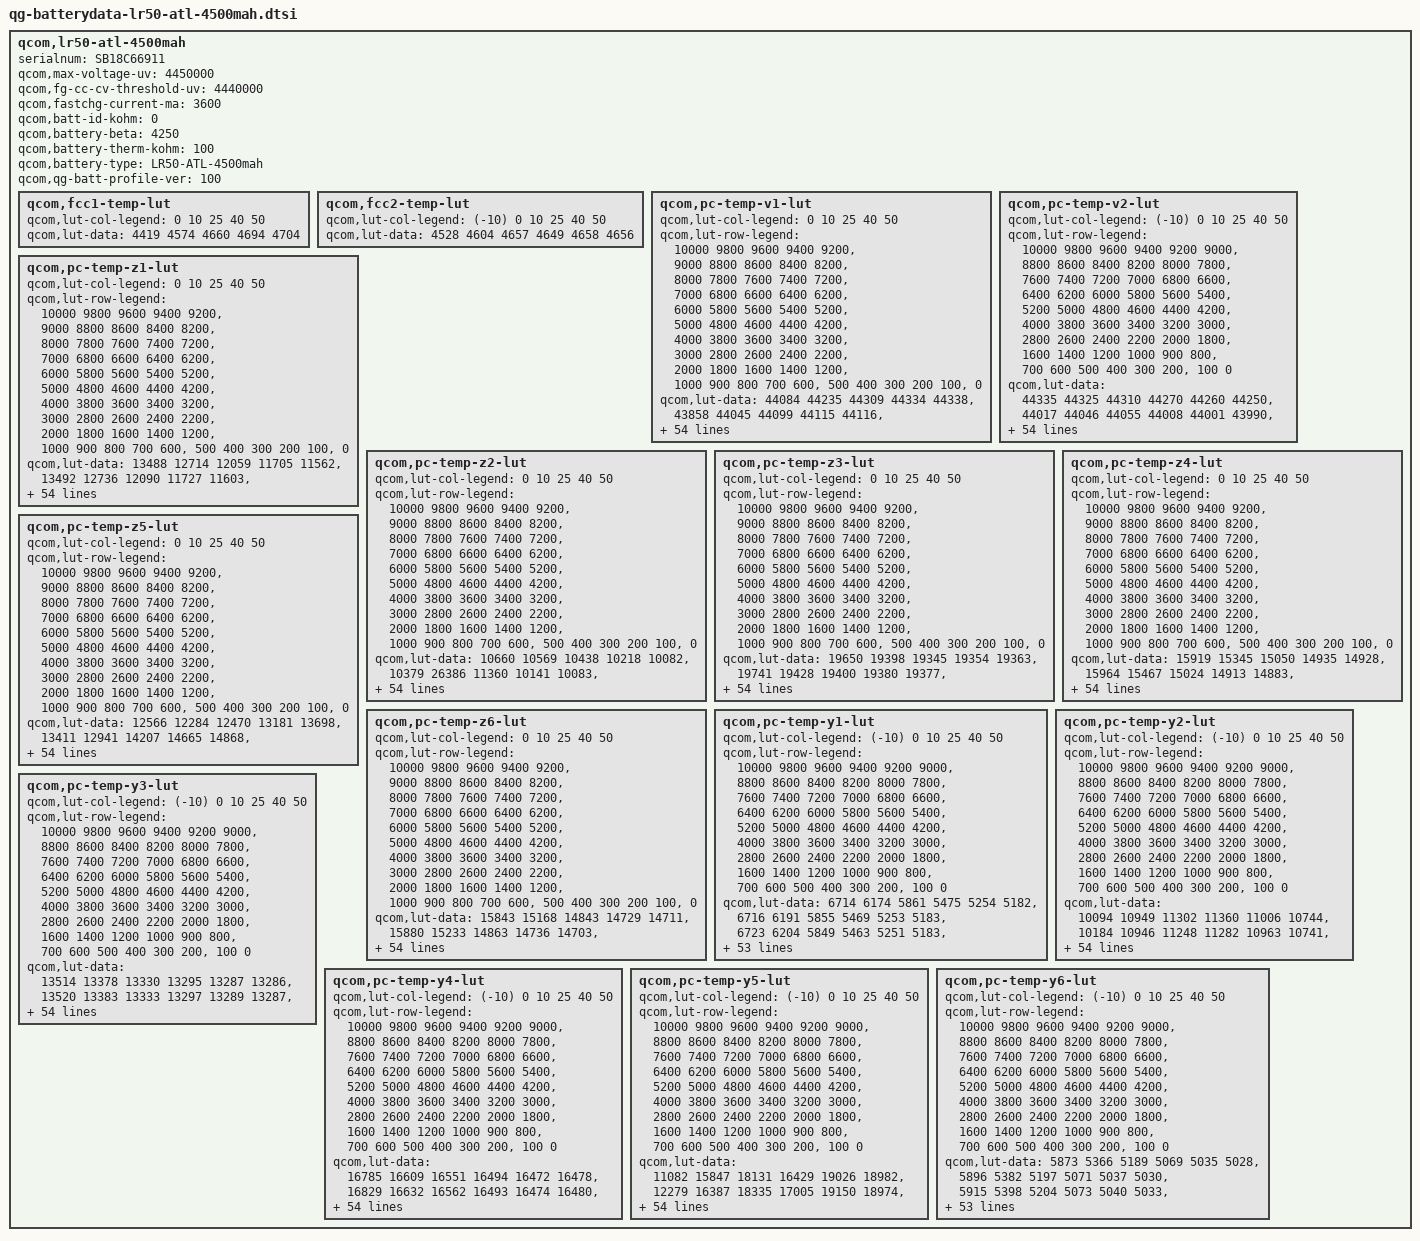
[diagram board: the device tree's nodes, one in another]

qcom,lr50-atl-4500mah {
	serialnum = "SB18C66911";
	qcom,max-voltage-uv = <4450000>;
	qcom,fg-cc-cv-threshold-uv = <4440000>;
	qcom,fastchg-current-ma = <3600>;
	qcom,batt-id-kohm = <0>;
	qcom,battery-beta = <4250>;
	qcom,battery-therm-kohm = <100>;
	qcom,battery-type = "LR50-ATL-4500mah";
	qcom,qg-batt-profile-ver = <100>;

	qcom,fcc1-temp-lut {
		qcom,lut-col-legend = <0 10 25 40 50>;
		qcom,lut-data = <4419 4574 4660 4694 4704>;
	};

	qcom,fcc2-temp-lut {
		qcom,lut-col-legend = <(-10) 0 10 25 40 50>;
		qcom,lut-data = <4528 4604 4657 4649 4658 4656>;
	};

	qcom,pc-temp-v1-lut {
		qcom,lut-col-legend = <0 10 25 40 50>;
		qcom,lut-row-legend = <10000 9800 9600 9400 9200>,
			<9000 8800 8600 8400 8200>,
			<8000 7800 7600 7400 7200>,
			<7000 6800 6600 6400 6200>,
			<6000 5800 5600 5400 5200>,
			<5000 4800 4600 4400 4200>,
			<4000 3800 3600 3400 3200>,
			<3000 2800 2600 2400 2200>,
			<2000 1800 1600 1400 1200>,
			<1000 900 800 700 600>,
			<500 400 300 200 100>,
			<0>;
		qcom,lut-data = <44084 44235 44309 44334 44338>,
			<43858 44045 44099 44115 44116>,
			<43631 43827 43902 43912 43913>,
			<43404 43604 43689 43709 43714>,
			<43174 43377 43467 43497 43504>,
			<42936 43142 43237 43274 43283>,
			<42692 42903 43000 43041 43050>,
			<42451 42657 42759 42802 42811>,
			<42212 42409 42511 42557 42569>,
			<41976 42165 42263 42309 42324>,
			<41746 41924 42019 42066 42081>,
			<41521 41688 41777 41825 41839>,
			<41301 41458 41541 41589 41600>,
			<41092 41235 41309 41355 41365>,
			<40885 41020 41086 41127 41135>,
			<40676 40812 40876 40907 40914>,
			<40465 40607 40673 40695 40700>,
			<40268 40403 40472 40493 40498>,
			<40091 40209 40275 40300 40308>,
			<39925 40039 40091 40115 40125>,
			<39762 39873 39930 39948 39957>,
			<39606 39673 39746 39773 39782>,
			<39445 39427 39449 39529 39543>,
			<39263 39198 39121 39235 39246>,
			<39074 38994 38955 39038 39046>,
			<38904 38816 38863 38920 38936>,
			<38740 38700 38778 38818 38838>,
			<38610 38617 38683 38713 38720>,
			<38528 38543 38592 38614 38602>,
			<38464 38469 38506 38519 38503>,
			<38408 38402 38426 38428 38418>,
			<38355 38339 38352 38345 38339>,
			<38308 38283 38284 38271 38264>,
			<38267 38231 38221 38203 38193>,
			<38230 38186 38165 38136 38124>,
			<38195 38143 38113 38074 38058>,
			<38163 38103 38061 38013 37991>,
			<38127 38065 38014 37960 37925>,
			<38075 38012 37955 37896 37849>,
			<38002 37927 37870 37801 37746>,
			<37914 37821 37765 37683 37623>,
			<37794 37705 37649 37566 37500>,
			<37662 37569 37516 37441 37372>,
			<37528 37404 37355 37287 37209>,
			<37365 37251 37200 37139 37066>,
			<37226 37142 37098 37048 36992>,
			<37178 37118 37066 37016 36960>,
			<37142 37089 37042 36992 36938>,
			<37112 37063 37024 36973 36915>,
			<37082 37031 36988 36928 36862>,
			<37034 36878 36804 36716 36626>,
			<36831 36461 36389 36291 36196>,
			<36360 35869 35815 35719 35623>,
			<35706 35018 35030 34939 34842>,
			<34574 33637 33812 33745 33641>,
			<30000 30000 30000 30000 30000>;
	};

	qcom,pc-temp-v2-lut {
		qcom,lut-col-legend = <(-10) 0 10 25 40 50>;
		qcom,lut-row-legend = <10000 9800 9600 9400 9200 9000>,
			<8800 8600 8400 8200 8000 7800>,
			<7600 7400 7200 7000 6800 6600>,
			<6400 6200 6000 5800 5600 5400>,
			<5200 5000 4800 4600 4400 4200>,
			<4000 3800 3600 3400 3200 3000>,
			<2800 2600 2400 2200 2000 1800>,
			<1600 1400 1200 1000 900 800>,
			<700 600 500 400 300 200>,
			<100 0>;
		qcom,lut-data = <44335 44325 44310 44270 44260 44250>,
			<44017 44046 44055 44008 44001 43990>,
			<43730 43786 43812 43758 43755 43743>,
			<43478 43550 43583 43524 43523 43512>,
			<43261 43337 43368 43305 43307 43296>,
			<43043 43115 43144 43079 43082 43074>,
			<42811 42874 42901 42838 42845 42839>,
			<42572 42626 42653 42593 42602 42599>,
			<42327 42380 42405 42346 42358 42356>,
			<42073 42133 42156 42099 42112 42109>,
			<41823 41893 41911 41856 41868 41866>,
			<41581 41658 41670 41618 41627 41627>,
			<41344 41429 41434 41384 41391 41391>,
			<41115 41202 41203 41153 41160 41160>,
			<40894 40979 40978 40928 40935 40935>,
			<40657 40751 40765 40711 40718 40717>,
			<40379 40518 40563 40500 40510 40506>,
			<40094 40277 40349 40300 40310 40304>,
			<39846 40017 40104 40122 40123 40117>,
			<39621 39751 39851 39941 39939 39935>,
			<39413 39521 39607 39723 39743 39747>,
			<39220 39319 39369 39470 39539 39556>,
			<39036 39134 39162 39235 39325 39349>,
			<38842 38963 38984 39020 39081 39100>,
			<38640 38804 38825 38831 38863 38874>,
			<38474 38654 38681 38685 38713 38722>,
			<38344 38513 38551 38563 38592 38600>,
			<38238 38382 38432 38452 38480 38487>,
			<38158 38253 38323 38350 38376 38382>,
			<38094 38137 38221 38256 38281 38285>,
			<38037 38043 38125 38168 38198 38200>,
			<37985 37963 38036 38087 38122 38121>,
			<37935 37902 37953 38015 38047 38046>,
			<37880 37857 37873 37951 37974 37975>,
			<37824 37818 37809 37887 37899 37897>,
			<37766 37779 37763 37820 37824 37810>,
			<37705 37741 37722 37751 37746 37716>,
			<37640 37697 37677 37677 37655 37615>,
			<37567 37643 37630 37598 37556 37508>,
			<37487 37576 37566 37514 37459 37409>,
			<37404 37479 37472 37425 37366 37320>,
			<37315 37359 37360 37324 37270 37226>,
			<37222 37238 37225 37207 37166 37120>,
			<37125 37096 37063 37065 36999 36942>,
			<37037 36943 36915 36942 36903 36850>,
			<36944 36822 36832 36888 36853 36806>,
			<36897 36781 36797 36873 36842 36795>,
			<36848 36739 36764 36855 36830 36778>,
			<36799 36698 36709 36834 36807 36751>,
			<36751 36647 36622 36773 36736 36671>,
			<36690 36569 36385 36556 36475 36375>,
			<36596 36340 35899 36063 35973 35870>,
			<36402 35757 35201 35433 35331 35219>,
			<35976 34829 34181 34595 34468 34346>,
			<35065 33516 32703 33336 33235 33072>,
			<33973 31884 28001 28237 28418 28444>;
	};

	qcom,pc-temp-z1-lut {
		qcom,lut-col-legend = <0 10 25 40 50>;
		qcom,lut-row-legend = <10000 9800 9600 9400 9200>,
			<9000 8800 8600 8400 8200>,
			<8000 7800 7600 7400 7200>,
			<7000 6800 6600 6400 6200>,
			<6000 5800 5600 5400 5200>,
			<5000 4800 4600 4400 4200>,
			<4000 3800 3600 3400 3200>,
			<3000 2800 2600 2400 2200>,
			<2000 1800 1600 1400 1200>,
			<1000 900 800 700 600>,
			<500 400 300 200 100>,
			<0>;
		qcom,lut-data = <13488 12714 12059 11705 11562>,
			<13492 12736 12090 11727 11603>,
			<13498 12735 12092 11723 11603>,
			<13507 12733 12084 11721 11602>,
			<13513 12728 12072 11719 11603>,
			<13504 12715 12062 11716 11602>,
			<13478 12702 12052 11713 11599>,
			<13457 12683 12042 11710 11598>,
			<13440 12663 12032 11706 11598>,
			<13429 12647 12026 11703 11599>,
			<13429 12633 12023 11703 11600>,
			<13433 12624 12022 11704 11600>,
			<13435 12619 12021 11705 11601>,
			<13421 12615 12021 11704 11601>,
			<13400 12611 12020 11703 11602>,
			<13386 12608 12019 11704 11603>,
			<13372 12606 12017 11704 11604>,
			<13362 12601 12018 11705 11605>,
			<13353 12598 12020 11706 11606>,
			<13344 12603 12022 11708 11607>,
			<13342 12610 12023 11709 11608>,
			<13347 12613 12025 11711 11610>,
			<13352 12615 12026 11711 11611>,
			<13358 12616 12028 11712 11612>,
			<13367 12617 12031 11713 11613>,
			<13370 12619 12036 11717 11616>,
			<13382 12621 12040 11721 11619>,
			<13392 12624 12045 11725 11622>,
			<13395 12630 12050 11728 11626>,
			<13399 12643 12056 11732 11629>,
			<13401 12657 12064 11735 11632>,
			<13402 12660 12070 11739 11636>,
			<13404 12660 12076 11744 11641>,
			<13403 12662 12081 11749 11645>,
			<13399 12667 12087 11754 11649>,
			<13401 12675 12093 11759 11652>,
			<13422 12685 12099 11764 11656>,
			<13446 12700 12106 11769 11661>,
			<13464 12712 12113 11774 11665>,
			<13496 12723 12122 11777 11668>,
			<13513 12733 12131 11781 11671>,
			<13519 12741 12139 11785 11674>,
			<13528 12749 12146 11790 11678>,
			<13547 12765 12156 11794 11681>,
			<13565 12776 12170 11799 11684>,
			<13581 12783 12183 11806 11686>,
			<13566 12787 12181 11804 11685>,
			<13516 12798 12179 11803 11685>,
			<13531 12788 12182 11805 11687>,
			<13516 12788 12187 11809 11691>,
			<13527 12809 12207 11815 11695>,
			<13596 12836 12214 11824 11701>,
			<13609 12838 12229 11835 11712>,
			<13618 12861 12253 11850 11726>,
			<13618 12861 12253 11850 11726>,
			<13618 12861 12253 11850 11726>;
	};

	qcom,pc-temp-z2-lut {
		qcom,lut-col-legend = <0 10 25 40 50>;
		qcom,lut-row-legend = <10000 9800 9600 9400 9200>,
			<9000 8800 8600 8400 8200>,
			<8000 7800 7600 7400 7200>,
			<7000 6800 6600 6400 6200>,
			<6000 5800 5600 5400 5200>,
			<5000 4800 4600 4400 4200>,
			<4000 3800 3600 3400 3200>,
			<3000 2800 2600 2400 2200>,
			<2000 1800 1600 1400 1200>,
			<1000 900 800 700 600>,
			<500 400 300 200 100>,
			<0>;
		qcom,lut-data = <10660 10569 10438 10218 10082>,
			<10379 26386 11360 10141 10083>,
			<10272 18958 11442 10302 10201>,
			<10235 11003 10911 10302 10215>,
			<10211 10371 10421 10295 10209>,
			<10197 10343 10368 10279 10207>,
			<10186 10321 10328 10236 10198>,
			<10181 10300 10299 10197 10186>,
			<10180 10286 10275 10168 10152>,
			<10180 10283 10263 10149 10113>,
			<10179 10282 10264 10151 10110>,
			<10179 10283 10268 10161 10117>,
			<10182 10291 10271 10168 10127>,
			<10188 10305 10280 10173 10157>,
			<10196 10329 10310 10178 10183>,
			<10206 10365 10669 10184 10189>,
			<10217 10392 11037 10193 10192>,
			<10233 10415 10889 10206 10190>,
			<10281 10432 10481 10226 10174>,
			<10337 10443 10359 10242 10164>,
			<10353 10452 10371 10258 10180>,
			<10357 10467 10388 10270 10200>,
			<10362 10493 10411 11048 10196>,
			<10373 10507 10435 12967 10176>,
			<10386 10499 10426 13325 10160>,
			<10398 10486 10366 11500 10148>,
			<10409 10480 10335 10154 10140>,
			<10418 10475 10371 10220 10297>,
			<10425 10473 10420 10345 10584>,
			<10430 10480 10438 10387 10607>,
			<10437 10487 10448 10407 10423>,
			<10445 10490 10452 10412 10272>,
			<10454 10496 10447 10368 10208>,
			<10462 10501 10442 10309 10158>,
			<10470 10504 10441 10279 10096>,
			<10479 10508 10441 10257 10033>,
			<10489 10516 10446 10255 10021>,
			<10501 10530 10465 10288 10077>,
			<10516 10545 10486 10333 10153>,
			<10536 10561 10507 10401 10235>,
			<10558 10578 10530 10474 10316>,
			<10582 10589 10545 10482 10361>,
			<10624 10602 10559 10472 10396>,
			<10774 10627 10578 10470 10432>,
			<10828 10768 10617 10471 10431>,
			<10798 10968 10659 10416 10225>,
			<10758 11429 10652 10362 10214>,
			<10686 11518 10644 10338 10219>,
			<10644 11619 10678 10345 10232>,
			<10624 11766 10727 10416 10300>,
			<10507 11591 10728 10373 10265>,
			<10465 11298 10705 10209 10053>,
			<10341 10957 10633 10111 9956>,
			<10041 10681 10539 10036 9890>,
			<10041 10681 10539 10036 9890>,
			<10041 10681 10539 10036 9890>;
	};

	qcom,pc-temp-z3-lut {
		qcom,lut-col-legend = <0 10 25 40 50>;
		qcom,lut-row-legend = <10000 9800 9600 9400 9200>,
			<9000 8800 8600 8400 8200>,
			<8000 7800 7600 7400 7200>,
			<7000 6800 6600 6400 6200>,
			<6000 5800 5600 5400 5200>,
			<5000 4800 4600 4400 4200>,
			<4000 3800 3600 3400 3200>,
			<3000 2800 2600 2400 2200>,
			<2000 1800 1600 1400 1200>,
			<1000 900 800 700 600>,
			<500 400 300 200 100>,
			<0>;
		qcom,lut-data = <19650 19398 19345 19354 19363>,
			<19741 19428 19400 19380 19377>,
			<19793 19524 19432 19420 19406>,
			<19824 19616 19472 19444 19431>,
			<19842 19627 19502 19459 19446>,
			<19848 19631 19507 19468 19457>,
			<19853 19632 19510 19473 19466>,
			<19853 19632 19511 19477 19471>,
			<19843 19631 19513 19481 19472>,
			<19832 19628 19513 19483 19473>,
			<19829 19620 19509 19480 19471>,
			<19823 19614 19501 19469 19465>,
			<19819 19608 19494 19462 19459>,
			<19817 19603 19489 19457 19455>,
			<19815 19596 19487 19454 19451>,
			<19814 19588 19503 19449 19447>,
			<19814 19581 19519 19444 19441>,
			<19813 19573 19508 19439 19434>,
			<19792 19569 19477 19433 19426>,
			<19764 19569 19460 19426 19417>,
			<19761 19571 19451 19419 19408>,
			<19768 19577 19447 19412 19401>,
			<19775 19602 19460 19406 19397>,
			<19783 19617 19483 19402 19394>,
			<19793 19614 19481 19396 19390>,
			<19796 19607 19455 19383 19373>,
			<19797 19599 19439 19374 19360>,
			<19797 19588 19436 19380 19397>,
			<19790 19581 19434 19394 19466>,
			<19778 19577 19437 19412 19478>,
			<19769 19575 19446 19437 19467>,
			<19763 19575 19454 19448 19455>,
			<19757 19577 19464 19446 19446>,
			<19752 19577 19470 19442 19436>,
			<19746 19577 19469 19436 19422>,
			<19740 19577 19467 19426 19405>,
			<19734 19575 19463 19416 19393>,
			<19728 19568 19456 19402 19384>,
			<19720 19563 19450 19394 19379>,
			<19710 19559 19446 19395 19378>,
			<19698 19554 19443 19397 19377>,
			<19685 19546 19438 19397 19379>,
			<19653 19534 19432 19396 19388>,
			<19382 19525 19430 19398 19399>,
			<19315 19492 19424 19397 19402>,
			<19310 19445 19404 19379 19377>,
			<19308 19324 19397 19369 19370>,
			<19302 19304 19394 19364 19352>,
			<19297 19292 19374 19354 19345>,
			<19296 19286 19362 19345 19339>,
			<19295 19296 19383 19359 19356>,
			<19298 19305 19387 19392 19386>,
			<19315 19330 19394 19395 19392>,
			<19337 19475 19400 19400 19396>,
			<19337 19475 19400 19400 19396>,
			<19337 19475 19400 19400 19396>;
	};

	qcom,pc-temp-z4-lut {
		qcom,lut-col-legend = <0 10 25 40 50>;
		qcom,lut-row-legend = <10000 9800 9600 9400 9200>,
			<9000 8800 8600 8400 8200>,
			<8000 7800 7600 7400 7200>,
			<7000 6800 6600 6400 6200>,
			<6000 5800 5600 5400 5200>,
			<5000 4800 4600 4400 4200>,
			<4000 3800 3600 3400 3200>,
			<3000 2800 2600 2400 2200>,
			<2000 1800 1600 1400 1200>,
			<1000 900 800 700 600>,
			<500 400 300 200 100>,
			<0>;
		qcom,lut-data = <15919 15345 15050 14935 14928>,
			<15964 15467 15024 14913 14883>,
			<15915 15379 15099 14954 14901>,
			<15746 15250 15048 14947 14919>,
			<15561 15165 14982 14906 14886>,
			<15443 15094 14940 14874 14859>,
			<15346 15037 14905 14848 14835>,
			<15269 14989 14874 14825 14814>,
			<15207 14949 14846 14802 14793>,
			<15153 14918 14821 14782 14775>,
			<15106 14893 14797 14767 14761>,
			<15065 14870 14777 14755 14750>,
			<15026 14851 14766 14746 14742>,
			<14987 14833 14760 14739 14736>,
			<14951 14813 14749 14733 14732>,
			<14923 14796 14707 14727 14728>,
			<14899 14790 14669 14722 14726>,
			<14880 14788 14681 14717 14722>,
			<14867 14786 14715 14712 14718>,
			<14856 14772 14726 14711 14716>,
			<14838 14752 14725 14711 14715>,
			<14808 14752 14725 14712 14715>,
			<14792 14774 14784 14749 14749>,
			<14801 14803 14879 14849 14854>,
			<14820 14841 14896 14886 14893>,
			<14840 14877 14894 14892 14891>,
			<14870 14880 14891 14894 14887>,
			<14889 14868 14879 14878 14836>,
			<14887 14855 14860 14843 14747>,
			<14881 14842 14840 14807 14724>,
			<14873 14828 14816 14766 14720>,
			<14862 14813 14792 14739 14717>,
			<14850 14797 14768 14724 14710>,
			<14837 14784 14749 14715 14706>,
			<14824 14772 14738 14712 14706>,
			<14811 14762 14730 14711 14708>,
			<14797 14754 14726 14711 14708>,
			<14784 14747 14724 14711 14707>,
			<14770 14742 14724 14711 14705>,
			<14757 14739 14729 14719 14717>,
			<14747 14736 14735 14732 14738>,
			<14739 14730 14734 14733 14737>,
			<14742 14720 14727 14727 14722>,
			<14999 14710 14722 14726 14721>,
			<14979 14699 14710 14721 14718>,
			<14938 14692 14683 14692 14690>,
			<14938 14820 14679 14694 14691>,
			<14939 14833 14666 14686 14690>,
			<14942 14841 14670 14669 14670>,
			<14935 14839 14669 14657 14651>,
			<14932 14830 14666 14680 14684>,
			<14929 14839 14686 14685 14695>,
			<14942 14826 14687 14690 14702>,
			<14952 14697 14688 14692 14703>,
			<14952 14697 14688 14692 14703>,
			<14952 14697 14688 14692 14703>;
	};

	qcom,pc-temp-z5-lut {
		qcom,lut-col-legend = <0 10 25 40 50>;
		qcom,lut-row-legend = <10000 9800 9600 9400 9200>,
			<9000 8800 8600 8400 8200>,
			<8000 7800 7600 7400 7200>,
			<7000 6800 6600 6400 6200>,
			<6000 5800 5600 5400 5200>,
			<5000 4800 4600 4400 4200>,
			<4000 3800 3600 3400 3200>,
			<3000 2800 2600 2400 2200>,
			<2000 1800 1600 1400 1200>,
			<1000 900 800 700 600>,
			<500 400 300 200 100>,
			<0>;
		qcom,lut-data = <12566 12284 12470 13181 13698>,
			<13411 12941 14207 14665 14868>,
			<13903 14318 14601 16294 16662>,
			<14162 15604 15792 17048 17440>,
			<14371 15914 16960 18231 18810>,
			<14633 16045 17287 19024 20108>,
			<14902 16214 17484 19553 21357>,
			<15092 16558 17788 20154 22471>,
			<15308 16955 18277 21198 23403>,
			<15544 17261 18840 22169 24273>,
			<15786 17538 19461 22477 25120>,
			<16149 17867 20110 22632 25941>,
			<16582 18290 20628 22917 26842>,
			<17175 18808 21038 23600 27945>,
			<17963 19592 21962 24414 28984>,
			<19113 20522 28028 25190 29876>,
			<20803 20972 33909 25968 30632>,
			<21615 21129 31937 26637 30708>,
			<21565 21352 26228 27308 30179>,
			<21498 22282 23912 27669 29530>,
			<22071 24340 23485 27237 28982>,
			<25499 29234 23621 26548 28304>,
			<29924 42436 29198 26071 27127>,
			<35842 50068 37969 25176 25105>,
			<42451 46003 37400 23563 22526>,
			<45146 38974 27343 19207 18199>,
			<45639 34167 20899 16198 15301>,
			<44854 29703 19457 16288 20213>,
			<42089 27331 18726 16616 29291>,
			<38148 26542 18905 17662 30869>,
			<36039 26118 19775 20946 29631>,
			<34996 26424 20979 23854 28888>,
			<34313 27791 23357 25912 29058>,
			<33902 29339 26084 27402 29278>,
			<33693 31352 28649 28082 28247>,
			<33751 33061 30947 28520 25567>,
			<33897 33572 31551 28414 24670>,
			<34104 33837 31586 26683 24715>,
			<34702 34187 31468 25401 24741>,
			<35858 34861 31003 26143 24525>,
			<36327 35347 30181 27308 24194>,
			<34913 33739 28720 26649 24137>,
			<31482 30906 26653 23883 24531>,
			<15110 30962 26926 24460 27949>,
			<12373 29319 27822 25612 30829>,
			<12495 24266 27207 23301 23054>,
			<12428 13602 24757 19937 20084>,
			<12264 12470 24583 19679 17147>,
			<12135 12175 20170 19536 17998>,
			<12119 12101 18250 19891 20224>,
			<12117 12408 22803 21251 22177>,
			<12224 12490 19431 21168 20120>,
			<12312 13067 19014 19236 18199>,
			<12562 28674 18812 17920 16642>,
			<12562 28674 18812 17920 16642>,
			<12562 28674 18812 17920 16642>;
	};

	qcom,pc-temp-z6-lut {
		qcom,lut-col-legend = <0 10 25 40 50>;
		qcom,lut-row-legend = <10000 9800 9600 9400 9200>,
			<9000 8800 8600 8400 8200>,
			<8000 7800 7600 7400 7200>,
			<7000 6800 6600 6400 6200>,
			<6000 5800 5600 5400 5200>,
			<5000 4800 4600 4400 4200>,
			<4000 3800 3600 3400 3200>,
			<3000 2800 2600 2400 2200>,
			<2000 1800 1600 1400 1200>,
			<1000 900 800 700 600>,
			<500 400 300 200 100>,
			<0>;
		qcom,lut-data = <15843 15168 14843 14729 14711>,
			<15880 15233 14863 14736 14703>,
			<15880 15229 14907 14776 14728>,
			<15808 15213 14900 14780 14743>,
			<15718 15189 14888 14774 14741>,
			<15662 15150 14875 14767 14738>,
			<15614 15117 14858 14759 14733>,
			<15572 15091 14844 14750 14727>,
			<15532 15068 14832 14743 14720>,
			<15496 15048 14819 14735 14713>,
			<15466 15030 14806 14726 14705>,
			<15440 15014 14793 14716 14697>,
			<15416 15001 14784 14708 14691>,
			<15393 14989 14778 14702 14687>,
			<15372 14976 14772 14697 14682>,
			<15354 14964 14764 14692 14678>,
			<15337 14956 14757 14687 14673>,
			<15321 14950 14753 14681 14668>,
			<15302 14945 14750 14676 14661>,
			<15284 14939 14747 14672 14655>,
			<15275 14932 14742 14667 14649>,
			<15268 14935 14740 14664 14645>,
			<15265 14959 14772 14680 14659>,
			<15274 14981 14825 14723 14701>,
			<15291 14997 14832 14737 14716>,
			<15304 15009 14821 14732 14708>,
			<15319 15009 14810 14725 14700>,
			<15328 14999 14802 14720 14698>,
			<15325 14990 14796 14715 14697>,
			<15317 14984 14791 14710 14694>,
			<15311 14979 14786 14706 14687>,
			<15305 14974 14782 14701 14680>,
			<15300 14970 14777 14695 14674>,
			<15294 14965 14773 14690 14667>,
			<15287 14961 14769 14685 14660>,
			<15282 14958 14765 14680 14653>,
			<15277 14955 14762 14675 14647>,
			<15273 14952 14758 14668 14641>,
			<15270 14951 14757 14664 14637>,
			<15267 14951 14758 14668 14642>,
			<15265 14951 14760 14674 14649>,
			<15262 14948 14758 14675 14650>,
			<15258 14941 14754 14672 14650>,
			<15245 14937 14753 14673 14654>,
			<15207 14921 14747 14672 14655>,
			<15189 14899 14727 14651 14630>,
			<15189 14892 14723 14647 14627>,
			<15190 14886 14717 14640 14618>,
			<15190 14886 14708 14627 14605>,
			<15188 14885 14703 14618 14593>,
			<15192 14891 14714 14635 14617>,
			<15203 14904 14729 14657 14641>,
			<15226 14919 14737 14665 14650>,
			<15256 14951 14746 14672 14657>,
			<15256 14951 14746 14672 14657>,
			<15256 14951 14746 14672 14657>;
	};

	qcom,pc-temp-y1-lut {
		qcom,lut-col-legend = <(-10) 0 10 25 40 50>;
		qcom,lut-row-legend = <10000 9800 9600 9400 9200 9000>,
			<8800 8600 8400 8200 8000 7800>,
			<7600 7400 7200 7000 6800 6600>,
			<6400 6200 6000 5800 5600 5400>,
			<5200 5000 4800 4600 4400 4200>,
			<4000 3800 3600 3400 3200 3000>,
			<2800 2600 2400 2200 2000 1800>,
			<1600 1400 1200 1000 900 800>,
			<700 600 500 400 300 200>,
			<100 0>;
		qcom,lut-data = <6714 6174 5861 5475 5254 5182>,
			<6716 6191 5855 5469 5253 5183>,
			<6723 6204 5849 5463 5251 5183>,
			<6731 6213 5843 5457 5250 5183>,
			<6738 6218 5838 5452 5249 5183>,
			<6740 6219 5835 5448 5247 5183>,
			<6741 6213 5834 5446 5246 5181>,
			<6742 6207 5833 5443 5245 5180>,
			<6733 6206 5831 5440 5245 5180>,
			<6705 6204 5828 5436 5244 5180>,
			<6690 6204 5824 5434 5243 5180>,
			<6700 6209 5819 5434 5242 5181>,
			<6717 6213 5814 5434 5242 5181>,
			<6731 6213 5809 5433 5242 5181>,
			<6756 6211 5805 5432 5242 5181>,
			<6772 6209 5805 5431 5243 5182>,
			<6775 6208 5808 5432 5244 5183>,
			<6775 6207 5810 5433 5245 5184>,
			<6774 6211 5813 5435 5246 5185>,
			<6768 6219 5815 5437 5247 5185>,
			<6761 6224 5815 5439 5248 5186>,
			<6751 6228 5815 5441 5250 5187>,
			<6743 6230 5815 5444 5251 5188>,
			<6739 6226 5817 5448 5253 5190>,
			<6733 6220 5820 5453 5255 5191>,
			<6731 6221 5824 5456 5256 5193>,
			<6727 6230 5830 5459 5258 5195>,
			<6724 6234 5833 5462 5260 5197>,
			<6722 6226 5839 5467 5263 5201>,
			<6718 6216 5842 5472 5267 5203>,
			<6716 6219 5840 5476 5271 5205>,
			<6718 6231 5837 5479 5274 5207>,
			<6723 6236 5839 5484 5276 5208>,
			<6730 6238 5850 5489 5278 5211>,
			<6736 6239 5855 5494 5281 5213>,
			<6737 6237 5853 5498 5283 5214>,
			<6739 6232 5851 5502 5286 5214>,
			<6740 6234 5854 5504 5287 5216>,
			<6734 6248 5861 5506 5288 5218>,
			<6719 6258 5865 5507 5289 5219>,
			<6714 6246 5869 5509 5290 5220>,
			<6715 6230 5878 5513 5291 5221>,
			<6717 6238 5898 5521 5293 5225>,
			<6727 6238 5894 5525 5295 5227>,
			<6739 6262 5916 5530 5302 5231>,
			<6768 6264 5912 5542 5305 5233>,
			<6782 6255 5914 5544 5304 5233>,
			<6773 6275 5922 5545 5304 5231>,
			<6773 6307 5918 5545 5304 5231>,
			<6832 6310 5926 5546 5304 5234>,
			<6881 6299 5934 5545 5307 5236>,
			<6942 6363 5952 5555 5314 5243>,
			<7053 6472 6028 5579 5320 5250>,
			<7233 6719 6159 5611 5331 5258>,
			<7233 6719 6159 5611 5331 5258>,
			<7233 6719 6159 5611 5331 5258>;
	};

	qcom,pc-temp-y2-lut {
		qcom,lut-col-legend = <(-10) 0 10 25 40 50>;
		qcom,lut-row-legend = <10000 9800 9600 9400 9200 9000>,
			<8800 8600 8400 8200 8000 7800>,
			<7600 7400 7200 7000 6800 6600>,
			<6400 6200 6000 5800 5600 5400>,
			<5200 5000 4800 4600 4400 4200>,
			<4000 3800 3600 3400 3200 3000>,
			<2800 2600 2400 2200 2000 1800>,
			<1600 1400 1200 1000 900 800>,
			<700 600 500 400 300 200>,
			<100 0>;
		qcom,lut-data = <10094 10949 11302 11360 11006 10744>,
			<10184 10946 11248 11282 10963 10741>,
			<10284 10941 11195 11201 10908 10731>,
			<10380 10936 11146 11126 10853 10715>,
			<10460 10930 11101 11063 10808 10698>,
			<10512 10923 11063 11020 10782 10680>,
			<10544 10913 11026 10992 10766 10656>,
			<10564 10904 10999 10973 10756 10629>,
			<10564 10904 10985 10960 10755 10601>,
			<10553 10907 10975 10952 10754 10574>,
			<10547 10910 10974 10946 10749 10569>,
			<10660 10920 10986 10941 10730 10593>,
			<10814 10934 11003 10939 10714 10616>,
			<10834 10958 11018 10945 10712 10615>,
			<10827 10994 11038 10961 10713 10603>,
			<10823 11032 11074 10984 10719 10601>,
			<10865 11078 11140 11028 10744 10604>,
			<10922 11113 11187 11078 10778 10616>,
			<10939 11127 11205 11143 10846 10661>,
			<10947 11138 11218 11200 10943 10739>,
			<10951 11153 11232 11218 11063 10888>,
			<10954 11177 11248 11228 11209 11133>,
			<10956 11195 11267 11232 11247 11208>,
			<10753 11201 11293 11233 11121 11037>,
			<10062 11206 11314 11235 11009 10882>,
			<9719 11210 11320 11244 11025 10910>,
			<9697 11214 11325 11263 11071 10993>,
			<9686 11216 11330 11285 11111 11062>,
			<9681 11208 11337 11316 11147 11121>,
			<9678 11199 11342 11341 11174 11176>,
			<9676 11218 11340 11351 11188 11232>,
			<9674 11276 11337 11358 11201 11285>,
			<9672 11296 11338 11359 11234 11319>,
			<9669 11233 11345 11360 11300 11351>,
			<9667 11142 11344 11362 11327 11361>,
			<9665 11074 11323 11360 11305 11327>,
			<9664 11008 11291 11354 11270 11275>,
			<9663 10934 11256 11334 11229 11208>,
			<9662 10861 11212 11296 11178 11116>,
			<9661 10747 11165 11266 11143 11078>,
			<9661 10231 11116 11242 11119 11070>,
			<9660 9703 11046 11231 11110 11042>,
			<9660 9682 10940 11224 11108 10957>,
			<9660 9673 10841 11233 10985 10891>,
			<9659 9671 10789 11175 10865 10719>,
			<9659 9664 10610 11104 10779 10648>,
			<9658 9661 10494 11064 10806 10703>,
			<9657 9659 10318 11063 10821 10701>,
			<9656 9657 9870 11060 10868 10761>,
			<9654 9655 9698 11078 10869 10731>,
			<9651 9653 9671 11066 10823 10670>,
			<9649 9650 9657 10990 10758 10576>,
			<9648 9648 9651 10877 10652 10500>,
			<9647 9648 9650 10787 10512 10362>,
			<9647 9648 9650 10787 10512 10362>,
			<9647 9648 9650 10787 10512 10362>;
	};

	qcom,pc-temp-y3-lut {
		qcom,lut-col-legend = <(-10) 0 10 25 40 50>;
		qcom,lut-row-legend = <10000 9800 9600 9400 9200 9000>,
			<8800 8600 8400 8200 8000 7800>,
			<7600 7400 7200 7000 6800 6600>,
			<6400 6200 6000 5800 5600 5400>,
			<5200 5000 4800 4600 4400 4200>,
			<4000 3800 3600 3400 3200 3000>,
			<2800 2600 2400 2200 2000 1800>,
			<1600 1400 1200 1000 900 800>,
			<700 600 500 400 300 200>,
			<100 0>;
		qcom,lut-data = <13514 13378 13330 13295 13287 13286>,
			<13520 13383 13333 13297 13289 13287>,
			<13531 13390 13338 13299 13291 13289>,
			<13544 13399 13342 13302 13293 13290>,
			<13554 13406 13346 13303 13295 13291>,
			<13559 13409 13347 13304 13296 13293>,
			<13559 13409 13348 13304 13297 13294>,
			<13560 13409 13348 13304 13298 13296>,
			<13558 13409 13349 13304 13299 13296>,
			<13548 13408 13350 13305 13300 13296>,
			<13543 13408 13351 13308 13301 13297>,
			<13553 13406 13350 13312 13301 13298>,
			<13566 13405 13349 13315 13302 13299>,
			<13553 13407 13349 13315 13303 13299>,
			<13493 13414 13349 13315 13304 13300>,
			<13461 13414 13350 13314 13306 13300>,
			<13472 13401 13353 13313 13309 13301>,
			<13486 13388 13354 13313 13310 13303>,
			<13483 13385 13352 13313 13310 13304>,
			<13463 13383 13347 13313 13309 13306>,
			<13447 13380 13342 13312 13308 13306>,
			<13440 13376 13336 13311 13305 13304>,
			<13434 13372 13332 13308 13302 13301>,
			<13427 13370 13330 13302 13295 13294>,
			<13420 13368 13328 13297 13291 13288>,
			<13413 13365 13327 13297 13291 13289>,
			<13406 13361 13325 13296 13291 13290>,
			<13400 13358 13325 13296 13290 13290>,
			<13402 13354 13324 13297 13287 13289>,
			<13413 13350 13323 13298 13285 13288>,
			<13427 13343 13323 13298 13286 13287>,
			<13452 13330 13323 13298 13286 13287>,
			<13485 13326 13322 13298 13287 13287>,
			<13519 13332 13319 13298 13289 13289>,
			<13560 13341 13317 13299 13289 13290>,
			<13606 13349 13319 13300 13290 13289>,
			<13661 13358 13323 13300 13290 13289>,
			<13721 13366 13326 13300 13290 13288>,
			<13782 13372 13330 13300 13290 13288>,
			<13847 13380 13332 13299 13290 13288>,
			<13901 13398 13333 13300 13292 13291>,
			<13945 13423 13334 13300 13293 13292>,
			<13985 13454 13336 13301 13293 13290>,
			<14021 13493 13334 13298 13286 13284>,
			<14072 13482 13330 13292 13288 13287>,
			<14077 13599 13341 13300 13293 13296>,
			<14165 13695 13347 13305 13301 13300>,
			<14269 13833 13360 13310 13305 13302>,
			<14425 14034 13374 13317 13308 13304>,
			<14721 14269 13432 13319 13307 13303>,
			<15660 14710 13584 13315 13301 13298>,
			<18341 16612 14002 13311 13300 13298>,
			<26095 24624 15685 13322 13306 13305>,
			<54003 65535 25720 13337 13319 13317>,
			<54003 65535 25720 13337 13319 13317>,
			<54003 65535 25720 13337 13319 13317>;
	};

	qcom,pc-temp-y4-lut {
		qcom,lut-col-legend = <(-10) 0 10 25 40 50>;
		qcom,lut-row-legend = <10000 9800 9600 9400 9200 9000>,
			<8800 8600 8400 8200 8000 7800>,
			<7600 7400 7200 7000 6800 6600>,
			<6400 6200 6000 5800 5600 5400>,
			<5200 5000 4800 4600 4400 4200>,
			<4000 3800 3600 3400 3200 3000>,
			<2800 2600 2400 2200 2000 1800>,
			<1600 1400 1200 1000 900 800>,
			<700 600 500 400 300 200>,
			<100 0>;
		qcom,lut-data = <16785 16609 16551 16494 16472 16478>,
			<16829 16632 16562 16493 16474 16480>,
			<16921 16681 16578 16494 16477 16482>,
			<17028 16738 16596 16496 16479 16484>,
			<17116 16784 16610 16499 16482 16486>,
			<17151 16801 16614 16502 16483 16486>,
			<17150 16801 16613 16507 16483 16486>,
			<17147 16801 16611 16512 16484 16485>,
			<17144 16803 16612 16516 16485 16486>,
			<17141 16808 16616 16519 16487 16488>,
			<17135 16815 16622 16521 16489 16489>,
			<17091 16829 16635 16523 16493 16491>,
			<17036 16841 16650 16525 16498 16493>,
			<17056 16843 16666 16532 16503 16497>,
			<17167 16843 16683 16547 16508 16501>,
			<17225 16846 16704 16562 16513 16506>,
			<17108 16858 16730 16582 16518 16510>,
			<16943 16867 16742 16604 16526 16516>,
			<16888 16824 16717 16639 16550 16528>,
			<16864 16736 16675 16669 16576 16544>,
			<16841 16695 16637 16658 16585 16560>,
			<16808 16677 16598 16604 16590 16579>,
			<16782 16663 16573 16557 16587 16581>,
			<16780 16648 16557 16520 16533 16532>,
			<16783 16634 16548 16497 16485 16485>,
			<16786 16620 16544 16496 16484 16482>,
			<16787 16608 16541 16498 16484 16481>,
			<16789 16594 16541 16500 16487 16482>,
			<16791 16575 16541 16504 16498 16489>,
			<16795 16560 16541 16509 16510 16498>,
			<16796 16565 16537 16515 16522 16509>,
			<16791 16583 16531 16523 16532 16521>,
			<16786 16592 16526 16530 16535 16530>,
			<16787 16594 16522 16537 16537 16537>,
			<16793 16596 16520 16540 16538 16540>,
			<16797 16603 16526 16535 16537 16538>,
			<16800 16615 16536 16527 16534 16535>,
			<16801 16629 16550 16519 16526 16527>,
			<16801 16643 16567 16511 16509 16514>,
			<16800 16661 16578 16508 16504 16511>,
			<16799 16692 16584 16507 16505 16518>,
			<16797 16717 16586 16507 16507 16524>,
			<16796 16709 16586 16506 16512 16529>,
			<16798 16695 16575 16488 16468 16468>,
			<16793 16670 16548 16477 16458 16455>,
			<16769 16666 16566 16489 16483 16489>,
			<16768 16670 16584 16506 16510 16527>,
			<16772 16688 16610 16530 16549 16570>,
			<16779 16706 16671 16568 16587 16608>,
			<16791 16734 16741 16596 16602 16616>,
			<16912 16777 16749 16575 16544 16537>,
			<17333 17028 16768 16525 16498 16503>,
			<18843 19344 17115 16542 16501 16503>,
			<29357 46262 25454 16592 16522 16521>,
			<29357 46262 25454 16592 16522 16521>,
			<29357 46262 25454 16592 16522 16521>;
	};

	qcom,pc-temp-y5-lut {
		qcom,lut-col-legend = <(-10) 0 10 25 40 50>;
		qcom,lut-row-legend = <10000 9800 9600 9400 9200 9000>,
			<8800 8600 8400 8200 8000 7800>,
			<7600 7400 7200 7000 6800 6600>,
			<6400 6200 6000 5800 5600 5400>,
			<5200 5000 4800 4600 4400 4200>,
			<4000 3800 3600 3400 3200 3000>,
			<2800 2600 2400 2200 2000 1800>,
			<1600 1400 1200 1000 900 800>,
			<700 600 500 400 300 200>,
			<100 0>;
		qcom,lut-data = <11082 15847 18131 16429 19026 18982>,
			<12279 16387 18335 17005 19150 18974>,
			<13421 16765 18379 17211 19143 18942>,
			<14483 17006 18297 17138 19030 18890>,
			<15445 17131 18123 16877 18842 18822>,
			<16285 17160 17883 16509 18601 18743>,
			<17149 17028 17427 15785 18194 18660>,
			<17815 16820 16895 15069 17751 18543>,
			<17894 16667 16506 14778 17441 18166>,
			<17834 16529 16168 14593 17147 17429>,
			<17810 16489 15800 14592 16803 16984>,
			<19194 16594 15307 15033 16301 16761>,
			<21071 16785 15018 15394 15821 16518>,
			<20790 17126 15100 15083 15424 16105>,
			<18561 17734 15348 14421 15112 15615>,
			<17401 18379 15866 14011 15102 15265>,
			<20382 19104 17237 13712 15294 14975>,
			<24207 19802 18820 13594 15395 14745>,
			<24110 20408 20867 14190 14888 14544>,
			<21971 20949 22534 15465 14273 14410>,
			<20905 21310 22396 17676 15521 15450>,
			<21344 21549 21534 21347 19413 18668>,
			<21875 21806 21209 22616 20833 19883>,
			<20723 22270 21279 20536 20226 19526>,
			<16442 22707 21378 18409 19428 19096>,
			<13726 22705 21368 18111 18895 18890>,
			<12793 22365 21259 17989 18363 18708>,
			<12274 21874 21301 18080 17521 18227>,
			<12194 21034 21625 18800 15999 16800>,
			<12166 19812 21798 19361 15164 15782>,
			<12168 17851 22300 19406 15370 15563>,
			<12421 15003 23005 19422 15822 15444>,
			<12747 14023 22429 19663 16403 15753>,
			<12885 14597 20252 20581 17278 17121>,
			<12971 15523 19285 21583 18293 18350>,
			<13088 16648 19638 22727 19789 19346>,
			<13323 18018 20150 23590 20892 20005>,
			<13515 18876 20578 23277 20909 19988>,
			<13539 19468 20992 22086 20813 19787>,
			<13546 19755 20968 21078 20791 19850>,
			<13540 17457 19871 20210 20844 20837>,
			<13394 14569 19083 20057 21587 22242>,
			<13144 14435 18556 20531 23819 23795>,
			<12689 14081 17368 19501 18682 19503>,
			<12739 13197 17046 16937 18278 18701>,
			<12589 13279 17048 17429 15920 17074>,
			<12731 13466 16143 17413 16513 15965>,
			<12748 13226 16003 17336 16371 15059>,
			<12800 13452 14076 18110 16236 14865>,
			<12852 13563 13621 17975 15893 14787>,
			<12113 13763 14206 17634 15751 14645>,
			<10914 12044 13851 17831 16539 15421>,
			<9767 9693 12510 19491 17071 15776>,
			<9046 8910 9470 21983 22576 21130>,
			<9046 8910 9470 21983 22576 21130>,
			<9046 8910 9470 21983 22576 21130>;
	};

	qcom,pc-temp-y6-lut {
		qcom,lut-col-legend = <(-10) 0 10 25 40 50>;
		qcom,lut-row-legend = <10000 9800 9600 9400 9200 9000>,
			<8800 8600 8400 8200 8000 7800>,
			<7600 7400 7200 7000 6800 6600>,
			<6400 6200 6000 5800 5600 5400>,
			<5200 5000 4800 4600 4400 4200>,
			<4000 3800 3600 3400 3200 3000>,
			<2800 2600 2400 2200 2000 1800>,
			<1600 1400 1200 1000 900 800>,
			<700 600 500 400 300 200>,
			<100 0>;
		qcom,lut-data = <5873 5366 5189 5069 5035 5028>,
			<5896 5382 5197 5071 5037 5030>,
			<5915 5398 5204 5073 5040 5033>,
			<5931 5412 5208 5074 5042 5035>,
			<5942 5421 5211 5076 5043 5036>,
			<5945 5424 5212 5077 5045 5038>,
			<5942 5421 5209 5078 5046 5039>,
			<5934 5416 5206 5079 5046 5040>,
			<5926 5413 5206 5080 5048 5040>,
			<5914 5410 5205 5082 5049 5041>,
			<5903 5409 5205 5084 5050 5042>,
			<5894 5409 5207 5086 5052 5043>,
			<5887 5410 5209 5089 5054 5045>,
			<5884 5411 5212 5092 5055 5046>,
			<5881 5413 5216 5096 5058 5048>,
			<5877 5414 5222 5099 5060 5049>,
			<5855 5410 5230 5104 5064 5051>,
			<5826 5403 5234 5110 5068 5054>,
			<5809 5386 5226 5120 5075 5059>,
			<5797 5363 5211 5128 5081 5064>,
			<5788 5351 5197 5125 5081 5068>,
			<5782 5346 5181 5109 5080 5071>,
			<5777 5341 5172 5093 5078 5071>,
			<5770 5338 5166 5079 5058 5051>,
			<5760 5335 5163 5069 5041 5033>,
			<5756 5333 5162 5069 5040 5033>,
			<5761 5331 5162 5070 5040 5033>,
			<5771 5329 5162 5071 5041 5034>,
			<5785 5328 5163 5073 5043 5035>,
			<5807 5327 5164 5075 5045 5037>,
			<5831 5328 5165 5078 5049 5040>,
			<5860 5333 5165 5080 5052 5043>,
			<5893 5340 5165 5083 5055 5047>,
			<5931 5353 5164 5087 5056 5050>,
			<5975 5371 5164 5088 5057 5052>,
			<6023 5394 5169 5088 5057 5051>,
			<6075 5423 5178 5087 5057 5050>,
			<6129 5457 5188 5085 5055 5047>,
			<6181 5500 5200 5083 5050 5044>,
			<6232 5545 5212 5082 5049 5043>,
			<6277 5588 5223 5083 5050 5047>,
			<6313 5635 5236 5084 5052 5049>,
			<6347 5692 5251 5084 5053 5049>,
			<6381 5756 5257 5079 5036 5028>,
			<6429 5759 5253 5072 5035 5028>,
			<6447 5891 5303 5084 5048 5045>,
			<6522 5983 5338 5093 5061 5059>,
			<6614 6122 5395 5104 5075 5072>,
			<6757 6305 5469 5120 5088 5085>,
			<7030 6516 5593 5129 5091 5087>,
			<7869 6908 5797 5121 5070 5061>,
			<10077 8502 6234 5105 5058 5052>,
			<16039 14937 7690 5124 5064 5058>,
			<37957 59341 17325 5158 5081 5074>,
			<37957 59341 17325 5158 5081 5074>,
			<37957 59341 17325 5158 5081 5074>;
	};

};
